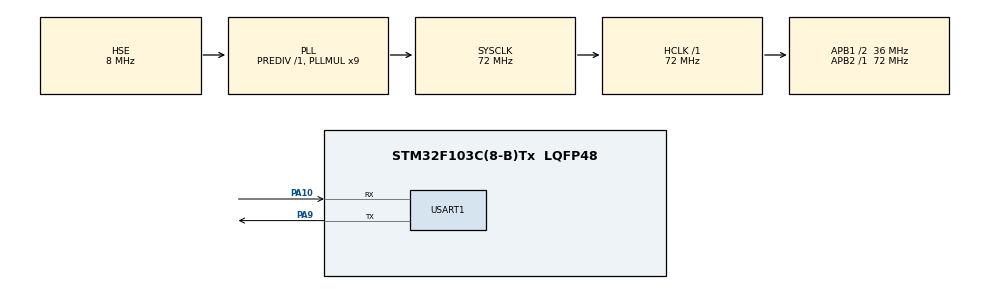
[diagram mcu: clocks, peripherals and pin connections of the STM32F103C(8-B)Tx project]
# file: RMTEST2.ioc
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Dma.Request0=USART1_RX
Dma.Request1=USART1_TX
Dma.USART1_RX.0.Direction=DMA_PERIPH_TO_MEMORY
Dma.USART1_RX.0.Instance=DMA1_Channel5
Dma.USART1_RX.0.MemDataAlignment=DMA_MDATAALIGN_BYTE
Dma.USART1_RX.0.MemInc=DMA_MINC_ENABLE
Dma.USART1_RX.0.Mode=DMA_NORMAL
Dma.USART1_RX.0.PeriphDataAlignment=DMA_PDATAALIGN_BYTE
Dma.USART1_RX.0.PeriphInc=DMA_PINC_DISABLE
Dma.USART1_RX.0.Priority=DMA_PRIORITY_MEDIUM
Dma.USART1_TX.1.Direction=DMA_MEMORY_TO_PERIPH
Dma.USART1_TX.1.Instance=DMA1_Channel4
Dma.USART1_TX.1.MemDataAlignment=DMA_MDATAALIGN_BYTE
Dma.USART1_TX.1.MemInc=DMA_MINC_ENABLE
Dma.USART1_TX.1.Mode=DMA_NORMAL
Dma.USART1_TX.1.PeriphDataAlignment=DMA_PDATAALIGN_BYTE
Dma.USART1_TX.1.PeriphInc=DMA_PINC_DISABLE
Dma.USART1_TX.1.Priority=DMA_PRIORITY_MEDIUM
Mcu.Family=STM32F1
Mcu.Name=STM32F103C(8-B)Tx
Mcu.Package=LQFP48
NVIC.DMA1_Channel4_IRQn=true\:0\:0\:false\:false\:true\:false\:true\:true
NVIC.DMA1_Channel5_IRQn=true\:0\:0\:false\:false\:true\:false\:true\:true
NVIC.PriorityGroup=NVIC_PRIORITYGROUP_4
NVIC.USART1_IRQn=true\:0\:0\:false\:false\:true\:true\:true\:true
PA10.Mode=Asynchronous
PA10.Signal=USART1_RX
PA13.Mode=Serial_Wire
PA13.Signal=SYS_JTMS-SWDIO
PA14.Mode=Serial_Wire
PA14.Signal=SYS_JTCK-SWCLK
PA9.GPIO_Mode=GPIO_MODE_AF_PP
PA9.Mode=Asynchronous
PA9.Signal=USART1_TX
PD0-OSC_IN.Mode=HSE-External-Oscillator
PD0-OSC_IN.Signal=RCC_OSC_IN
PD1-OSC_OUT.Mode=HSE-External-Oscillator
PD1-OSC_OUT.Signal=RCC_OSC_OUT
ProjectManager.HeapSize=0x200
ProjectManager.StackSize=0x400
ProjectManager.TargetToolchain=STM32CubeIDE
RCC.AHBFreq_Value=72000000
RCC.APB1CLKDivider=RCC_HCLK_DIV2
RCC.APB1Freq_Value=36000000
RCC.APB1TimFreq_Value=72000000
RCC.APB2Freq_Value=72000000
RCC.APB2TimFreq_Value=72000000
RCC.HCLKFreq_Value=72000000
RCC.PLLMUL=RCC_PLL_MUL9
RCC.PLLSourceVirtual=RCC_PLLSOURCE_HSE
RCC.SYSCLKFreq_VALUE=72000000
RCC.SYSCLKSource=RCC_SYSCLKSOURCE_PLLCLK
RCC.USBFreq_Value=72000000
USART1.VirtualMode=VM_ASYNC
board=custom

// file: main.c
/* USER CODE BEGIN Header */
/**
  ******************************************************************************
  * @file           : main.c
  * @brief          : Main program body
  ******************************************************************************
  * @attention
  *
  * Copyright (c) 2025 STMicroelectronics.
  * All rights reserved.
  * This software is licensed under terms that can be found in the LICENSE file
  * in the root directory of this software component.
  * If no LICENSE file comes with this software, it is provided AS-IS.
  *
  ******************************************************************************
  */
/* USER CODE END Header */
#include "main.h"
#include "dma.h"
#include "usart.h"
#include "gpio.h"
#include "math.h"
#include <string.h>
#include <stdio.h>
/* USER CODE BEGIN Includes */

#include "../../usercode/BSP/Inc/bsp_usart.h"
/* USER CODE END Includes */

/* USER CODE BEGIN PD */
#define PI 3.1415926f
#define FRAME_HEADER 0xAB
/* USER CODE END PD */

/* USER CODE BEGIN PV */
uint8_t rx_buffer[10];
uint8_t tx_buffer[10];

static float phase = 0.0f;
static const float step = 2 * PI / 100; // 每次相位增加步长

/* USER CODE END PV */

void SystemClock_Config(void);
/* USER CODE BEGIN PFP */

/* USER CODE BEGIN 3 */

/* USER CODE END 3 */

/* USER CODE END PFP */

/* USER CODE BEGIN 0 */
void Serialplot_Callback(unsigned char *data, uint16_t size)
{
    if (data == NULL || size == 0) {
        return;
    }

    // 检查帧头
    if (data[0] != FRAME_HEADER) {
        return;
    }

    // 解析 sin_val 和 cos_val
    float sin_val, cos_val;
    memcpy(&sin_val, &data[1], sizeof(float));
    memcpy(&cos_val, &data[5], sizeof(float));

    // 控制 LED1（sin）
    if (sin_val > 0.0f) {
        HAL_GPIO_WritePin(LED1_GPIO_Port, LED1_Pin, GPIO_PIN_SET);
    } else {
        HAL_GPIO_WritePin(LED1_GPIO_Port, LED1_Pin, GPIO_PIN_RESET);
    }

    // 控制 LED2（cos）
    if (cos_val > 0.0f) {
        HAL_GPIO_WritePin(LED2_GPIO_Port, LED2_Pin, GPIO_PIN_SET);
    } else {
        HAL_GPIO_WritePin(LED2_GPIO_Port, LED2_Pin, GPIO_PIN_RESET);
    }
}
/* USER CODE END 0 */

int main(void)
{

  /* MCU Configuration--------------------------------------------------------*/

  /* Reset of all peripherals, Initializes the Flash interface and the Systick. */
  HAL_Init();

  /* Configure the system clock */
  SystemClock_Config();

  /* Initialize all configured peripherals */
  MX_GPIO_Init();
  MX_DMA_Init();
  MX_USART1_UART_Init();
  /* USER CODE BEGIN 2 */
  Uart_Init(&huart1, rx_buffer, 10, Serialplot_Callback);

  /* USER CODE END 2 */

  /* Infinite loop */
while (1)
{

    /* USER CODE BEGIN 3 */

    phase += step;
    if (phase >= 2 * PI) {
        phase = 0.0f;
    }

    float sin_val = sinf(phase);
    float cos_val = cosf(phase);

    // 创建包含帧头和实际数据的缓冲区
    uint8_t frame_data[9];  // 1 (帧头) + 4 (sin_val) + 4 (cos_val)

    // 添加帧头
    frame_data[0] = FRAME_HEADER;

    // 将 sin_val 和 cos_val 转换为二进制并添加到帧中
    memcpy(&frame_data[1], &sin_val, sizeof(float));
    memcpy(&frame_data[5], &cos_val, sizeof(float));

    // 发送整个帧数据
    UART_Send_Data(&huart1, frame_data, sizeof(frame_data));

    HAL_Delay(50); // 控制发送频率
}
/* USER CODE END 3 */
}

void SystemClock_Config(void)
{
  RCC_OscInitTypeDef RCC_OscInitStruct = {0};
  RCC_ClkInitTypeDef RCC_ClkInitStruct = {0};

  /** Initializes the RCC Oscillators according to the specified parameters
  * in the RCC_OscInitTypeDef structure.
  */
  RCC_OscInitStruct.OscillatorType = RCC_OSCILLATORTYPE_HSE;
  RCC_OscInitStruct.HSEState = RCC_HSE_ON;
  RCC_OscInitStruct.HSEPredivValue = RCC_HSE_PREDIV_DIV1;
  RCC_OscInitStruct.HSIState = RCC_HSI_ON;
  RCC_OscInitStruct.PLL.PLLState = RCC_PLL_ON;
  RCC_OscInitStruct.PLL.PLLSource = RCC_PLLSOURCE_HSE;
  RCC_OscInitStruct.PLL.PLLMUL = RCC_PLL_MUL9;
  if (HAL_RCC_OscConfig(&RCC_OscInitStruct) != HAL_OK)
  {
    Error_Handler();
  }

  /** Initializes the CPU, AHB and APB buses clocks
  */
  RCC_ClkInitStruct.ClockType = RCC_CLOCKTYPE_HCLK|RCC_CLOCKTYPE_SYSCLK
                              |RCC_CLOCKTYPE_PCLK1|RCC_CLOCKTYPE_PCLK2;
  RCC_ClkInitStruct.SYSCLKSource = RCC_SYSCLKSOURCE_PLLCLK;
  RCC_ClkInitStruct.AHBCLKDivider = RCC_SYSCLK_DIV1;
  RCC_ClkInitStruct.APB1CLKDivider = RCC_HCLK_DIV2;
  RCC_ClkInitStruct.APB2CLKDivider = RCC_HCLK_DIV1;

  if (HAL_RCC_ClockConfig(&RCC_ClkInitStruct, FLASH_LATENCY_2) != HAL_OK)
  {
    Error_Handler();
  }
}

void Error_Handler(void)
{
  __disable_irq();
  while (1)
  {
  }
}
